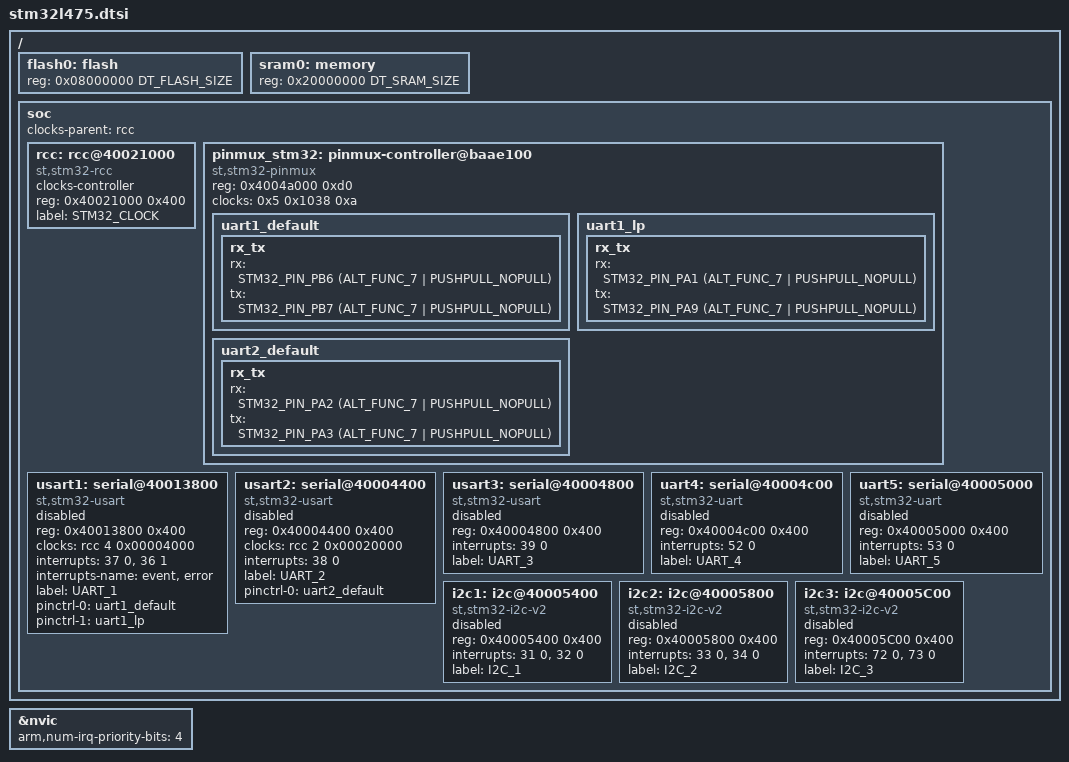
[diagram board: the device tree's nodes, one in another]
/*
 * Copyright (c) 2017 Linaro Limited
 *
 * SPDX-License-Identifier: Apache-2.0
 */

#include <arm/armv7-m.dtsi>
#include <st/mem.h>
#include <st/pinmux_stm32.h>


/ {
	flash0: flash {
		reg = <0x08000000 DT_FLASH_SIZE>;
	};

	sram0: memory {
		reg = <0x20000000 DT_SRAM_SIZE>;
	};

	soc {

		clocks-parent = <&rcc>;

		rcc: rcc@40021000 {
			compatible = "st,stm32-rcc";
            clocks-controller;
            #clocks-cells = <2>;
			reg = <0x40021000 0x400>;
			label = "STM32_CLOCK";
		};

		pinmux_stm32: pinmux-controller@baae100  {
			compatible = "st,stm32-pinmux";
			status = "ok";
			reg = <0x4004a000 0xd0>;
			clocks = <0x5 0x1038 0xa>;

			uart1_default: uart1_default {
				rx_tx {
					rx = <STM32_PIN_PB6 (ALT_FUNC_7 | PUSHPULL_NOPULL)>;
					tx = <STM32_PIN_PB7 (ALT_FUNC_7 | PUSHPULL_NOPULL)>;
				};
			};
			uart1_lp: uart1_lp {
				rx_tx {
					rx = <STM32_PIN_PA1 (ALT_FUNC_7 | PUSHPULL_NOPULL)>;
					tx = <STM32_PIN_PA9 (ALT_FUNC_7 | PUSHPULL_NOPULL)>;
				};
			};
			uart2_default: uart2_default {
				rx_tx {
					rx = <STM32_PIN_PA2 (ALT_FUNC_7 | PUSHPULL_NOPULL)>;
					tx = <STM32_PIN_PA3 (ALT_FUNC_7 | PUSHPULL_NOPULL)>;
				};
			};
		};

		usart1: serial@40013800 {
			compatible = "st,stm32-usart", "st,stm32-uart";
			reg = <0x40013800 0x400>;
			clocks = <&rcc 4 0x00004000>;
			interrupts = <37 0>, <36 1>;
			interrupts-name = "event", "error";
			status = "disabled";
			label = "UART_1";
			pinctrl-0 = <&uart1_default>;
			pinctrl-1 = <&uart1_lp>;
			pinctrl-names = "default", "sleep";
		};

		usart2: serial@40004400 {
			compatible = "st,stm32-usart", "st,stm32-uart";
			reg = <0x40004400 0x400>;
			clocks = <&rcc 2 0x00020000>;
			interrupts = <38 0>;
			status = "disabled";
			label = "UART_2";
			pinctrl-0 = <&uart2_default>;
			pinctrl-names = "default";
		};

		usart3: serial@40004800 {
			compatible = "st,stm32-usart", "st,stm32-uart";
			reg = <0x40004800 0x400>;
			interrupts = <39 0>;
			status = "disabled";
			label = "UART_3";
		};

		uart4: serial@40004c00 {
			compatible = "st,stm32-uart";
			reg = <0x40004c00 0x400>;
			interrupts = <52 0>;
			status = "disabled";
			label = "UART_4";
		};

		uart5: serial@40005000 {
			compatible = "st,stm32-uart";
			reg = <0x40005000 0x400>;
			interrupts = <53 0>;
			status = "disabled";
			label = "UART_5";
		};

		i2c1: i2c@40005400 {
			compatible = "st,stm32-i2c-v2";
			reg = <0x40005400 0x400>;
			interrupts = <31 0>, <32 0>;
			interrupt-names = "event", "error";
			status = "disabled";
			label= "I2C_1";
		};

		i2c2: i2c@40005800 {
			compatible = "st,stm32-i2c-v2";
			reg = <0x40005800 0x400>;
			interrupts = <33 0>, <34 0>;
			interrupt-names = "event", "error";
			status = "disabled";
			label= "I2C_2";
		};

		i2c3: i2c@40005C00 {
			compatible = "st,stm32-i2c-v2";
			reg = <0x40005C00 0x400>;
			interrupts = <72 0>, <73 0>;
			interrupt-names = "event", "error";
			status = "disabled";
			label= "I2C_3";
		};
	};
};

&nvic {
	arm,num-irq-priority-bits = <4>;
};
